AUTOSAR XML (schema 4.0)
package /MyComponents
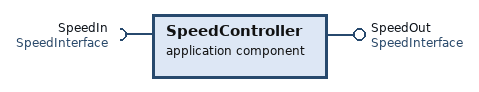
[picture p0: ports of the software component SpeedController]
  application software component type SpeedController
    provide port SpeedOut: provided-interface=SpeedInterface
    require port SpeedIn: required-interface=SpeedInterface
  application software component type BrakeSystem
    require port BrakeIn: required-interface=BrakeInterface
  sender receiver interface SpeedInterface
    data VehicleSpeed: type=uint16
  sender receiver interface BrakeInterface
    data BrakePressure: type=uint16
  app type uint16
